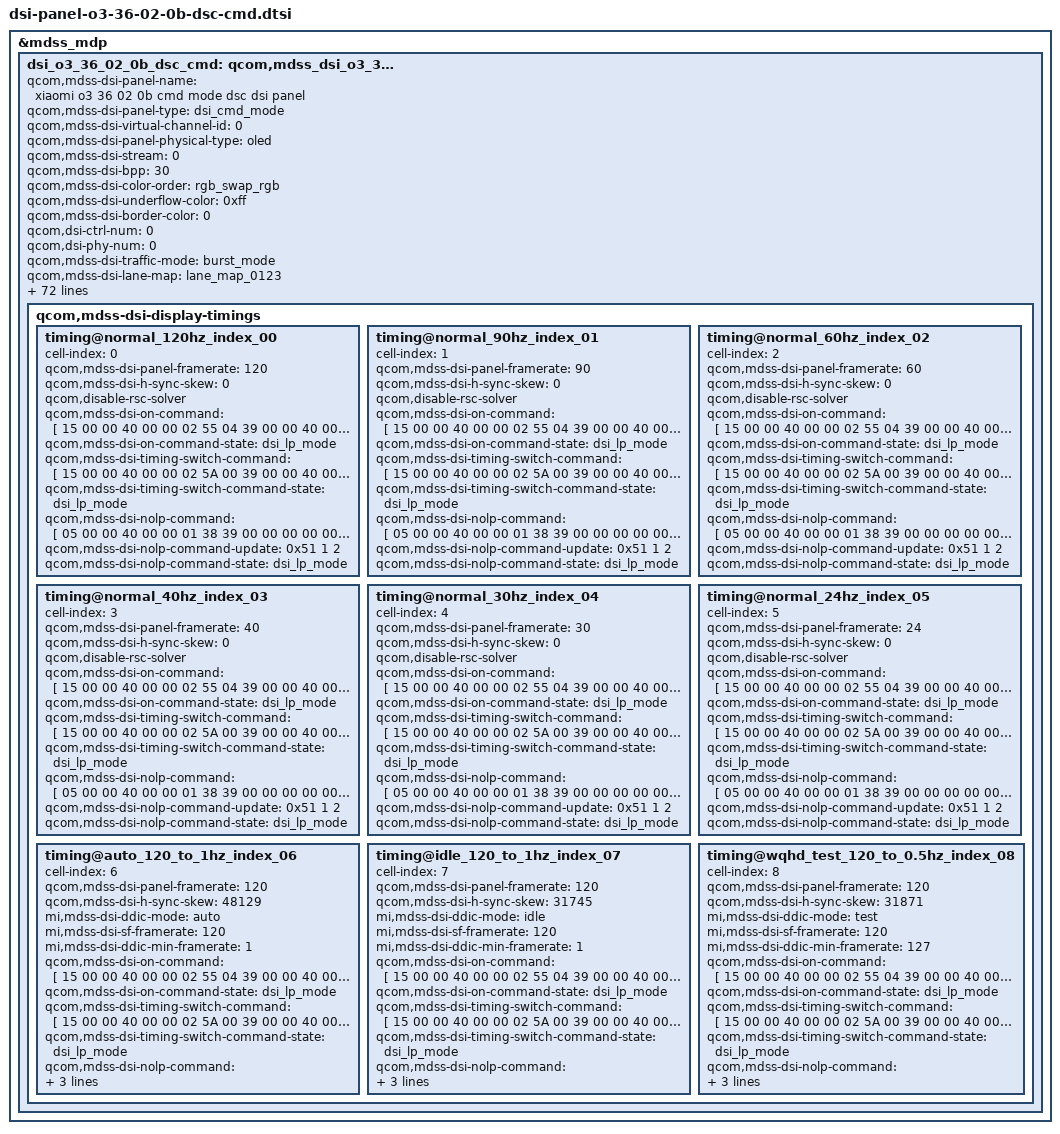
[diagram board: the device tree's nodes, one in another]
&mdss_mdp {
	dsi_o3_36_02_0b_dsc_cmd: qcom,mdss_dsi_o3_36_02_0b_dsc_cmd {
		qcom,mdss-dsi-panel-name = "xiaomi o3 36 02 0b cmd mode dsc dsi panel";
		qcom,mdss-dsi-panel-type = "dsi_cmd_mode";
		qcom,mdss-dsi-virtual-channel-id = <0>;
		qcom,mdss-dsi-panel-physical-type = "oled";
		qcom,mdss-dsi-stream = <0>;
		qcom,mdss-dsi-bpp = <30>;
		qcom,mdss-dsi-color-order = "rgb_swap_rgb";
		qcom,mdss-dsi-underflow-color = <0xff>;
		qcom,mdss-dsi-border-color = <0>;
		qcom,dsi-ctrl-num = <0>;
		qcom,dsi-phy-num = <0>;

		qcom,mdss-dsi-traffic-mode = "burst_mode";
		qcom,mdss-dsi-lane-map = "lane_map_0123";
		qcom,mdss-dsi-bllp-eof-power-mode;
		qcom,mdss-dsi-bllp-power-mode;
		qcom,mdss-dsi-lane-0-state;
		qcom,mdss-dsi-lane-1-state;
		qcom,mdss-dsi-lane-2-state;
		qcom,mdss-dsi-lane-3-state;
		qcom,mdss-dsi-dma-trigger = "trigger_sw";
		qcom,mdss-dsi-mdp-trigger = "none";
		qcom,mdss-dsi-reset-sequence = <1 10>, <0 1>, <1 25>;
		qcom,mdss-pan-physical-width-dimension = <663>;
		qcom,mdss-pan-physical-height-dimension = <1473>;
		qcom,mdss-dsi-te-pin-select = <1>;
		qcom,mdss-dsi-wr-mem-start = <0x2c>;
		qcom,mdss-dsi-wr-mem-continue = <0x3c>;
		qcom,mdss-dsi-te-dcs-command = <1>;
		qcom,mdss-dsi-te-check-enable;
		qcom,mdss-dsi-te-using-te-pin;
		qcom,mdss-dsi-tx-eot-append;
		qcom,mdss-dsi-lp11-init;

		qcom,mdss-dsi-bl-inverted-dbv;
		qcom,bl-update-flag = "delay_until_first_frame";

		qcom,mdss-dsi-dma-schedule-line = <1>;
		qcom,mdss-dsi-dma-schedule-window = <50>;

		mi,panel-id = <0x00004F33 0x0036020B>;

		mi,panel-on-dimming-delay = <120>;
		mi,max-brightness-clone = <16383>;

		mi,need-update-gamma-befor-init;

		qcom,spr-pack-type = "pentile";
		/*
		 * ###############################################################
		 * # Pentile SPR phases for SM8750 and later
		 * ###############################################################
		 * # RG/BG Type A    BG/RG Type A    GR/GB Type A    GB/GR Type A
		 * # R B R B ...     B R B R ...      R B R B ...     B R B R ...
		 * #  G G G G ...     G G G G ...    G G G G ...     G G G G ...
		 * #
		 * # RG/BG Type B    BG/RG Type B    GR/GB Type B    GB/GR Type B
		 * #  G G G G ...     G G G G ...    G G G G ...     G G G G ...
		 * # R B R B ...     B R B R ...      R B R B ...     B R B R ...
		 * ###############################################################
		 */
		qcom,spr-pentile-pack-type = "RG-BG Type A";

		mi,mdss-dsi-panel-wp-read-command = [06 01 00 01 00 00 01 A1];
		mi,mdss-dsi-panel-wp-read-command-state = "dsi_hs_mode";
		mi,mdss-dsi-panel-wp-read-length = <3>;
		mi,mdss-dsi-panel-cell-id-read-command = [06 01 00 01 00 00 01 AC];
		mi,mdss-dsi-panel-cell-id-read-command-state = "dsi_hs_mode";
		mi,mdss-dsi-panel-cell-id-read-length = <16>;

		mi,mdss-dsi-fac-bl-max-level = <2731>;
		mi,mdss-fac-brightness-max-level = <2731>;

		mi,doze-hbm-dbv-level = <207>;
		mi,doze-lbm-dbv-level = <25>;
		/* IRQF_ONESHOT | IRQF_TRIGGER_HEIGH */
		mi,esd-err-irq-gpio = <&tlmm 87 0x2004>;
		mi,esd-err-irq-gpio-flag = <0x2004>;

		mi,dc-feature-enabled;
		mi,ddic-round-corner-enabled;
		qcom,mdss-disable-cesta-hw-sleep;

		qcom,mdss-dsi-display-timings {
			timing@normal_120hz_index_00 {
				#include "dsi-panel-o3-36-02-0b-dsc-cmd-common.dtsi"
				cell-index = <0>;
				qcom,mdss-dsi-panel-framerate = <120>;
				qcom,mdss-dsi-h-sync-skew = <0>;
				qcom,disable-rsc-solver;
				qcom,mdss-dsi-on-command = [
					15 00 00 40 00 00 02 55 04
					39 00 00 40 00 00 03 81 01 19
					15 00 00 40 00 00 02 5A 01
					39 00 00 40 00 00 05 FF AA 55 A5 80
					15 00 00 40 00 00 02 6F 0A
					39 00 00 40 00 00 06 F6 70 70 70 70 70
					39 00 00 40 00 00 05 FF AA 55 A5 81
					15 00 00 40 00 00 02 6F 0D
					15 00 00 40 00 00 02 FB 80
					/*OSC Setting*/
					39 00 00 40 00 00 05 FF AA 55 A5 80
					15 00 00 40 00 00 02 6F 31
					39 00 00 40 00 00 03 F8 01 C4
					39 00 00 40 00 00 05 FF AA 55 A5 80
					15 00 00 40 00 00 02 6F 47
					15 00 00 40 00 00 02 F2 20
					15 00 00 40 00 00 02 6F 05
					15 00 00 40 00 00 02 F8 59
					15 00 00 40 00 00 02 6F 21
					15 00 00 40 00 00 02 F8 59
					39 00 00 40 00 00 05 FF AA 55 A5 81
					15 00 00 40 00 00 02 6F 0C
					15 00 00 40 00 00 02 FD 00
					15 00 00 40 00 00 02 6F 02
					15 00 00 40 00 00 02 F9 84
					15 00 00 40 00 00 02 6F 10
					15 00 00 40 00 00 02 FB 40
					39 00 00 40 00 00 05 FF AA 55 A5 80
					15 00 00 40 00 00 02 6F 48
					15 00 00 40 00 00 02 F2 00
					39 00 00 40 00 00 05 FF AA 55 A5 80
					15 00 00 40 00 00 02 6F 16
					39 00 00 40 00 00 03 F4 02 74
					39 00 00 40 00 00 05 FF AA 55 A5 80
					15 00 00 40 00 00 02 6F 42
					15 00 00 40 00 00 02 F4 00
					39 00 00 40 00 00 05 FF AA 55 A5 80
					15 00 00 40 00 00 02 6F 49
					15 00 00 40 00 00 02 F2 10
					39 00 00 40 00 00 05 FF AA 55 A5 81
					15 00 00 40 00 00 02 6F 05
					39 00 00 40 00 00 03 FE 3C 3C
					39 00 00 40 00 00 05 FF AA 55 A5 82
					15 00 00 40 00 00 02 6F 09
					15 00 00 40 00 00 02 F2 FF
					39 00 00 40 00 00 05 FF AA 55 A5 80
					15 00 00 40 00 00 02 6F 04
					15 00 00 40 00 00 02 F2 3C
					15 00 00 40 00 00 02 17 30
					/*120hz*/
					15 00 00 40 00 00 02 2F 00
					/*TE ON*/
					15 00 00 40 00 00 02 35 00
					/*600nit*/
					39 00 00 40 00 00 03 51 00 00
					15 00 00 40 00 00 02 6F 04
					/*AOD 60nit*/
					39 00 00 40 00 00 03 51 07 FF
					15 00 00 40 00 00 02 53 20
					39 00 00 40 00 00 05 2A 00 00 04 AF
					39 00 00 40 00 00 05 2B 00 00 0A 6D
					39 00 00 40 00 00 06 F0 55 AA 52 08 03
					15 00 00 00 00 00 02 6F 09
					39 00 00 40 00 00 07 DE 30 14 25 10 34 25
					39 00 00 40 00 00 06 F0 55 AA 52 08 07
					15 00 00 40 00 00 02 B0 04
					//Vesa YUV 1.2 8_16 VESASPEC_1200x2670, slice 30
					15 00 00 40 00 00 02 90 03
					15 00 00 40 00 00 02 6F 01
					15 00 00 40 00 00 02 90 43
					39 00 00 40 00 00 13 91 AB F0 00 1E D1 00 01 D2 00 D4 00 32 03 97 11 48 11 50
					39 00 00 40 00 00 06 F0 55 AA 52 08 01
					15 00 00 40 00 00 02 6F 02
					/*lvd off*/
					39 00 00 40 00 00 03 C7 00 00
					/*GIR ON*/
					39 00 00 40 00 00 03 5F 00 00
					/*normal Gramma*/
					15 00 00 40 00 00 02 26 00
					/*Skip mode setting*/
					39 00 00 00 00 00 06 F0 55 AA 52 08 00
					15 00 00 40 00 00 02 6F 1C
					39 00 00 40 00 00 11 BA 01 01 01 01 01 01 01 03 01 01 01 03 00 00 00 00
					15 00 00 40 00 00 02 6F 2C
					39 00 00 40 00 00 11 BA 01 01 01 01 01 03 03 01 01 03 03 01 00 00 00 00
					15 00 00 40 00 00 02 6F 3C
					39 00 00 40 00 00 11 BA 01 01 01 01 01 04 04 03 01 04 04 03 00 00 00 00
					15 00 00 40 00 00 02 6F 4C
					39 00 00 40 00 00 11 BA 01 01 01 01 0B 0B 0B 0B 0B 0B 0B 0B 00 00 00 00
					15 00 00 40 00 00 02 6F 5C
					39 00 00 40 00 00 11 BA 01 01 01 01 01 01 01 01 01 01 01 01 01 01 01 01
					15 00 00 40 00 00 02 6F 6C
					39 00 00 40 00 00 09 BA 00 00 00 00 00 00 00 00
					15 00 00 40 00 00 02 6F 74
					39 00 00 40 00 00 11 BA 00 01 02 03 04 05 07 09 0B 77 EF 00 03 0B 0B 03
					15 00 00 40 00 00 02 6F 84
					39 00 00 40 00 00 11 BA 00 01 02 03 04 05 07 09 0B 77 EF 00 03 0B 0B 03
					15 00 00 40 00 00 02 6F 94
					39 00 00 40 00 00 11 BA 00 00 00 00 00 00 00 00 00 00 00 00 00 00 00 00
					15 00 00 40 00 00 02 6F A4
					39 00 00 40 00 00 11 BA 01 01 01 01 00 01 01 00 00 01 01 00 00 00 1E 00
					15 00 00 40 00 00 02 6F B4
					39 00 00 40 00 00 05 BA 00 55 19 0C
					15 00 00 40 00 00 02 6F B8
					39 00 00 40 00 00 09 BA 00 00 00 00 00 10 00 00
					15 00 00 40 00 00 02 6F C0
					39 00 00 40 00 00 09 BA 00 00 00 00 00 10 00 00
					15 00 00 40 00 00 02 6F 6E
					39 00 00 40 00 00 03 D1 03 C8
					15 00 00 40 00 00 02 2F 30
					/*120hz*/
					15 00 00 40 00 00 02 5A 00
					39 00 00 40 00 00 06 F0 55 AA 52 08 00
					15 00 00 40 00 00 02 6F DE
					15 00 00 40 00 00 02 BA 00
					15 00 00 40 00 00 02 6F 04
					15 00 00 40 00 00 02 35 00
					15 00 00 40 00 00 02 6F 14
					15 00 00 40 00 00 02 35 00
					15 00 00 40 00 00 02 8C 00
					15 00 00 00 00 00 02 6D 00
					/* ACL On */
					39 00 00 40 00 00 06 F0 55 AA 52 08 00
					15 00 00 40 00 00 02 6F 17
					39 00 00 40 00 00 0B B0 1A AF 1C 03 1D 57 1E AB 1F FF
					15 00 00 40 00 00 02 6F 25
					39 00 00 00 00 00 0D B0 01 FF 01 65 01 65 01 65 01 65 01 65
					15 00 00 40 00 00 02 6F 55
					39 00 00 00 00 00 07 B0 00 00 0D 18 23 2C
					/* Display On */
					05 00 00 00 78 00 01 11
					05 00 00 00 00 00 01 29
				];
				qcom,mdss-dsi-on-command-state = "dsi_lp_mode";

				qcom,mdss-dsi-timing-switch-command = [
					15 00 00 40 00 00 02 5A 00
					39 00 00 40 00 00 06 F0 55 AA 52 08 00
					15 00 00 40 00 00 02 6F DE
					15 00 00 40 00 00 02 BA 00
					15 00 00 40 00 00 02 6F 04
					15 00 00 40 00 00 02 35 00
					15 00 00 40 00 00 02 6F 14
					15 00 00 40 00 00 02 35 00
					15 00 00 40 00 00 02 8C 00
					15 00 00 00 00 00 02 6D 00
				];
				qcom,mdss-dsi-timing-switch-command-state = "dsi_lp_mode";

				qcom,mdss-dsi-nolp-command = [
					05 00 00 40 00 00 01 38
					39 00 00 00 00 00 03 51 00 00
				];
				qcom,mdss-dsi-nolp-command-update = <0x51 1 2>;
				qcom,mdss-dsi-nolp-command-state = "dsi_lp_mode";
			};

			timing@normal_90hz_index_01 {
				#include "dsi-panel-o3-36-02-0b-dsc-cmd-common.dtsi"
				cell-index = <1>;
				qcom,mdss-dsi-panel-framerate = <90>;
				qcom,mdss-dsi-h-sync-skew = <0>;
				qcom,disable-rsc-solver;
				qcom,mdss-dsi-on-command = [
					15 00 00 40 00 00 02 55 04
					39 00 00 40 00 00 03 81 01 19
					15 00 00 40 00 00 02 5A 01
					39 00 00 40 00 00 05 FF AA 55 A5 80
					15 00 00 40 00 00 02 6F 0A
					39 00 00 40 00 00 06 F6 70 70 70 70 70
					39 00 00 40 00 00 05 FF AA 55 A5 81
					15 00 00 40 00 00 02 6F 0D
					15 00 00 40 00 00 02 FB 80
					/*OSC Setting*/
					39 00 00 40 00 00 05 FF AA 55 A5 80
					15 00 00 40 00 00 02 6F 31
					39 00 00 40 00 00 03 F8 01 C4
					39 00 00 40 00 00 05 FF AA 55 A5 80
					15 00 00 40 00 00 02 6F 47
					15 00 00 40 00 00 02 F2 20
					15 00 00 40 00 00 02 6F 05
					15 00 00 40 00 00 02 F8 59
					15 00 00 40 00 00 02 6F 21
					15 00 00 40 00 00 02 F8 59
					39 00 00 40 00 00 05 FF AA 55 A5 81
					15 00 00 40 00 00 02 6F 0C
					15 00 00 40 00 00 02 FD 00
					15 00 00 40 00 00 02 6F 02
					15 00 00 40 00 00 02 F9 84
					15 00 00 40 00 00 02 6F 10
					15 00 00 40 00 00 02 FB 40
					39 00 00 40 00 00 05 FF AA 55 A5 80
					15 00 00 40 00 00 02 6F 48
					15 00 00 40 00 00 02 F2 00
					39 00 00 40 00 00 05 FF AA 55 A5 80
					15 00 00 40 00 00 02 6F 16
					39 00 00 40 00 00 03 F4 02 74
					39 00 00 40 00 00 05 FF AA 55 A5 80
					15 00 00 40 00 00 02 6F 42
					15 00 00 40 00 00 02 F4 00
					39 00 00 40 00 00 05 FF AA 55 A5 80
					15 00 00 40 00 00 02 6F 49
					15 00 00 40 00 00 02 F2 10
					39 00 00 40 00 00 05 FF AA 55 A5 81
					15 00 00 40 00 00 02 6F 05
					39 00 00 40 00 00 03 FE 3C 3C
					39 00 00 40 00 00 05 FF AA 55 A5 82
					15 00 00 40 00 00 02 6F 09
					15 00 00 40 00 00 02 F2 FF
					39 00 00 40 00 00 05 FF AA 55 A5 80
					15 00 00 40 00 00 02 6F 04
					15 00 00 40 00 00 02 F2 3C
					15 00 00 40 00 00 02 17 30
					/*120hz*/
					15 00 00 40 00 00 02 2F 00
					/*TE ON*/
					15 00 00 40 00 00 02 35 00
					/*600nit*/
					39 00 00 40 00 00 03 51 00 00
					15 00 00 40 00 00 02 6F 04
					/*AOD 60nit*/
					39 00 00 40 00 00 03 51 07 FF
					15 00 00 40 00 00 02 53 20
					39 00 00 40 00 00 05 2A 00 00 04 AF
					39 00 00 40 00 00 05 2B 00 00 0A 6D
					39 00 00 40 00 00 06 F0 55 AA 52 08 03
					15 00 00 00 00 00 02 6F 09
					39 00 00 40 00 00 07 DE 30 14 25 10 34 25
					39 00 00 40 00 00 06 F0 55 AA 52 08 07
					15 00 00 40 00 00 02 B0 04
					//Vesa YUV 1.2 8_16 VESASPEC_1200x2670, slice 30
					15 00 00 40 00 00 02 90 03
					15 00 00 40 00 00 02 6F 01
					15 00 00 40 00 00 02 90 43
					39 00 00 40 00 00 13 91 AB F0 00 1E D1 00 01 D2 00 D4 00 32 03 97 11 48 11 50
					39 00 00 40 00 00 06 F0 55 AA 52 08 01
					15 00 00 40 00 00 02 6F 02
					/*lvd off*/
					39 00 00 40 00 00 03 C7 00 00
					/*GIR ON*/
					39 00 00 40 00 00 03 5F 00 00
					/*normal Gramma*/
					15 00 00 40 00 00 02 26 00
					/*Skip mode setting*/
					39 00 00 00 00 00 06 F0 55 AA 52 08 00
					15 00 00 40 00 00 02 6F 1C
					39 00 00 40 00 00 11 BA 01 01 01 01 01 01 01 03 01 01 01 03 00 00 00 00
					15 00 00 40 00 00 02 6F 2C
					39 00 00 40 00 00 11 BA 01 01 01 01 01 03 03 01 01 03 03 01 00 00 00 00
					15 00 00 40 00 00 02 6F 3C
					39 00 00 40 00 00 11 BA 01 01 01 01 01 04 04 03 01 04 04 03 00 00 00 00
					15 00 00 40 00 00 02 6F 4C
					39 00 00 40 00 00 11 BA 01 01 01 01 0B 0B 0B 0B 0B 0B 0B 0B 00 00 00 00
					15 00 00 40 00 00 02 6F 5C
					39 00 00 40 00 00 11 BA 01 01 01 01 01 01 01 01 01 01 01 01 01 01 01 01
					15 00 00 40 00 00 02 6F 6C
					39 00 00 40 00 00 09 BA 00 00 00 00 00 00 00 00
					15 00 00 40 00 00 02 6F 74
					39 00 00 40 00 00 11 BA 00 01 02 03 04 05 07 09 0B 77 EF 00 03 0B 0B 03
					15 00 00 40 00 00 02 6F 84
					39 00 00 40 00 00 11 BA 00 01 02 03 04 05 07 09 0B 77 EF 00 03 0B 0B 03
					15 00 00 40 00 00 02 6F 94
					39 00 00 40 00 00 11 BA 00 00 00 00 00 00 00 00 00 00 00 00 00 00 00 00
					15 00 00 40 00 00 02 6F A4
					39 00 00 40 00 00 11 BA 01 01 01 01 00 01 01 00 00 01 01 00 00 00 1E 00
					15 00 00 40 00 00 02 6F B4
					39 00 00 40 00 00 05 BA 00 55 19 0C
					15 00 00 40 00 00 02 6F B8
					39 00 00 40 00 00 09 BA 00 00 00 00 00 10 00 00
					15 00 00 40 00 00 02 6F C0
					39 00 00 40 00 00 09 BA 00 00 00 00 00 10 00 00
					15 00 00 40 00 00 02 6F 6E
					39 00 00 40 00 00 03 D1 03 C8
					15 00 00 40 00 00 02 2F 30
					/*90hz*/
					15 00 00 40 00 00 02 5A 00
					39 00 00 40 00 00 06 F0 55 AA 52 08 00
					15 00 00 40 00 00 02 6F DE
					15 00 00 40 00 00 02 BA 04
					15 00 00 40 00 00 02 6F 04
					15 00 00 40 00 00 02 35 00
					15 00 00 40 00 00 02 6F 14
					15 00 00 40 00 00 02 35 00
					15 00 00 40 00 00 02 8C 00
					15 00 00 00 00 00 02 6D 0B
					/* ACL On */
					39 00 00 40 00 00 06 F0 55 AA 52 08 00
					15 00 00 40 00 00 02 6F 17
					39 00 00 40 00 00 0B B0 1A AF 1C 03 1D 57 1E AB 1F FF
					15 00 00 40 00 00 02 6F 25
					39 00 00 00 00 00 0D B0 01 FF 01 65 01 65 01 65 01 65 01 65
					15 00 00 40 00 00 02 6F 55
					39 00 00 00 00 00 07 B0 00 00 0D 18 23 2C
					/* Display On */
					05 00 00 00 78 00 01 11
					05 00 00 00 00 00 01 29
				];
				qcom,mdss-dsi-on-command-state = "dsi_lp_mode";

				qcom,mdss-dsi-timing-switch-command = [
					15 00 00 40 00 00 02 5A 00
					39 00 00 40 00 00 06 F0 55 AA 52 08 00
					15 00 00 40 00 00 02 6F DE
					15 00 00 40 00 00 02 BA 04
					15 00 00 40 00 00 02 6F 04
					15 00 00 40 00 00 02 35 00
					15 00 00 40 00 00 02 6F 14
					15 00 00 40 00 00 02 35 00
					15 00 00 40 00 00 02 8C 00
					15 00 00 00 00 00 02 6D 0B
				];
				qcom,mdss-dsi-timing-switch-command-state = "dsi_lp_mode";

				qcom,mdss-dsi-nolp-command = [
					05 00 00 40 00 00 01 38
					39 00 00 00 00 00 03 51 00 00
				];
				qcom,mdss-dsi-nolp-command-update = <0x51 1 2>;
				qcom,mdss-dsi-nolp-command-state = "dsi_lp_mode";
			};

			timing@normal_60hz_index_02 {
				#include "dsi-panel-o3-36-02-0b-dsc-cmd-common.dtsi"
				cell-index = <2>;
				qcom,mdss-dsi-panel-framerate = <60>;
				qcom,mdss-dsi-h-sync-skew = <0>;
				qcom,disable-rsc-solver;
				qcom,mdss-dsi-on-command = [
					15 00 00 40 00 00 02 55 04
					39 00 00 40 00 00 03 81 01 19
					15 00 00 40 00 00 02 5A 01
					39 00 00 40 00 00 05 FF AA 55 A5 80
					15 00 00 40 00 00 02 6F 0A
					39 00 00 40 00 00 06 F6 70 70 70 70 70
					39 00 00 40 00 00 05 FF AA 55 A5 81
					15 00 00 40 00 00 02 6F 0D
					15 00 00 40 00 00 02 FB 80
					/*OSC Setting*/
					39 00 00 40 00 00 05 FF AA 55 A5 80
					15 00 00 40 00 00 02 6F 31
					39 00 00 40 00 00 03 F8 01 C4
					39 00 00 40 00 00 05 FF AA 55 A5 80
					15 00 00 40 00 00 02 6F 47
					15 00 00 40 00 00 02 F2 20
					15 00 00 40 00 00 02 6F 05
					15 00 00 40 00 00 02 F8 59
					15 00 00 40 00 00 02 6F 21
					15 00 00 40 00 00 02 F8 59
					39 00 00 40 00 00 05 FF AA 55 A5 81
					15 00 00 40 00 00 02 6F 0C
					15 00 00 40 00 00 02 FD 00
					15 00 00 40 00 00 02 6F 02
					15 00 00 40 00 00 02 F9 84
					15 00 00 40 00 00 02 6F 10
					15 00 00 40 00 00 02 FB 40
					39 00 00 40 00 00 05 FF AA 55 A5 80
					15 00 00 40 00 00 02 6F 48
					15 00 00 40 00 00 02 F2 00
					39 00 00 40 00 00 05 FF AA 55 A5 80
					15 00 00 40 00 00 02 6F 16
					39 00 00 40 00 00 03 F4 02 74
					39 00 00 40 00 00 05 FF AA 55 A5 80
					15 00 00 40 00 00 02 6F 42
					15 00 00 40 00 00 02 F4 00
					39 00 00 40 00 00 05 FF AA 55 A5 80
					15 00 00 40 00 00 02 6F 49
					15 00 00 40 00 00 02 F2 10
					39 00 00 40 00 00 05 FF AA 55 A5 81
					15 00 00 40 00 00 02 6F 05
					39 00 00 40 00 00 03 FE 3C 3C
					39 00 00 40 00 00 05 FF AA 55 A5 82
					15 00 00 40 00 00 02 6F 09
					15 00 00 40 00 00 02 F2 FF
					39 00 00 40 00 00 05 FF AA 55 A5 80
					15 00 00 40 00 00 02 6F 04
					15 00 00 40 00 00 02 F2 3C
					15 00 00 40 00 00 02 17 30
					/*120hz*/
					15 00 00 40 00 00 02 2F 00
					/*TE ON*/
					15 00 00 40 00 00 02 35 00
					/*600nit*/
					39 00 00 40 00 00 03 51 00 00
					15 00 00 40 00 00 02 6F 04
					/*AOD 60nit*/
					39 00 00 40 00 00 03 51 07 FF
					15 00 00 40 00 00 02 53 20
					39 00 00 40 00 00 05 2A 00 00 04 AF
					39 00 00 40 00 00 05 2B 00 00 0A 6D
					39 00 00 40 00 00 06 F0 55 AA 52 08 03
					15 00 00 00 00 00 02 6F 09
					39 00 00 40 00 00 07 DE 30 14 25 10 34 25
					39 00 00 40 00 00 06 F0 55 AA 52 08 07
					15 00 00 40 00 00 02 B0 04
					//Vesa YUV 1.2 8_16 VESASPEC_1200x2670, slice 30
					15 00 00 40 00 00 02 90 03
					15 00 00 40 00 00 02 6F 01
					15 00 00 40 00 00 02 90 43
					39 00 00 40 00 00 13 91 AB F0 00 1E D1 00 01 D2 00 D4 00 32 03 97 11 48 11 50
					39 00 00 40 00 00 06 F0 55 AA 52 08 01
					15 00 00 40 00 00 02 6F 02
					/*lvd off*/
					39 00 00 40 00 00 03 C7 00 00
					/*GIR ON*/
					39 00 00 40 00 00 03 5F 00 00
					/*normal Gramma*/
					15 00 00 40 00 00 02 26 00
					/*Skip mode setting*/
					39 00 00 00 00 00 06 F0 55 AA 52 08 00
					15 00 00 40 00 00 02 6F 1C
					39 00 00 40 00 00 11 BA 01 01 01 01 01 01 01 03 01 01 01 03 00 00 00 00
					15 00 00 40 00 00 02 6F 2C
					39 00 00 40 00 00 11 BA 01 01 01 01 01 03 03 01 01 03 03 01 00 00 00 00
					15 00 00 40 00 00 02 6F 3C
					39 00 00 40 00 00 11 BA 01 01 01 01 01 04 04 03 01 04 04 03 00 00 00 00
					15 00 00 40 00 00 02 6F 4C
					39 00 00 40 00 00 11 BA 01 01 01 01 0B 0B 0B 0B 0B 0B 0B 0B 00 00 00 00
					15 00 00 40 00 00 02 6F 5C
					39 00 00 40 00 00 11 BA 01 01 01 01 01 01 01 01 01 01 01 01 01 01 01 01
					15 00 00 40 00 00 02 6F 6C
					39 00 00 40 00 00 09 BA 00 00 00 00 00 00 00 00
					15 00 00 40 00 00 02 6F 74
					39 00 00 40 00 00 11 BA 00 01 02 03 04 05 07 09 0B 77 EF 00 03 0B 0B 03
					15 00 00 40 00 00 02 6F 84
					39 00 00 40 00 00 11 BA 00 01 02 03 04 05 07 09 0B 77 EF 00 03 0B 0B 03
					15 00 00 40 00 00 02 6F 94
					39 00 00 40 00 00 11 BA 00 00 00 00 00 00 00 00 00 00 00 00 00 00 00 00
					15 00 00 40 00 00 02 6F A4
					39 00 00 40 00 00 11 BA 01 01 01 01 00 01 01 00 00 01 01 00 00 00 1E 00
					15 00 00 40 00 00 02 6F B4
					39 00 00 40 00 00 05 BA 00 55 19 0C
					15 00 00 40 00 00 02 6F B8
					39 00 00 40 00 00 09 BA 00 00 00 00 00 10 00 00
					15 00 00 40 00 00 02 6F C0
					39 00 00 40 00 00 09 BA 00 00 00 00 00 10 00 00
					15 00 00 40 00 00 02 6F 6E
					39 00 00 40 00 00 03 D1 03 C8
					15 00 00 40 00 00 02 2F 30
					/*60hz*/
					15 00 00 40 00 00 02 5A 00
					39 00 00 40 00 00 06 F0 55 AA 52 08 00
					15 00 00 40 00 00 02 6F DE
					15 00 00 40 00 00 02 BA 04
					15 00 00 40 00 00 02 6F 04
					15 00 00 40 00 00 02 35 01
					15 00 00 40 00 00 02 6F 14
					15 00 00 40 00 00 02 35 00
					15 00 00 40 00 00 02 8C 02
					15 00 00 00 00 00 02 6D 01
					/* ACL On */
					39 00 00 40 00 00 06 F0 55 AA 52 08 00
					15 00 00 40 00 00 02 6F 17
					39 00 00 40 00 00 0B B0 1A AF 1C 03 1D 57 1E AB 1F FF
					15 00 00 40 00 00 02 6F 25
					39 00 00 00 00 00 0D B0 01 FF 01 65 01 65 01 65 01 65 01 65
					15 00 00 40 00 00 02 6F 55
					39 00 00 00 00 00 07 B0 00 00 0D 18 23 2C
					/* Display On */
					05 00 00 00 78 00 01 11
					05 00 00 00 00 00 01 29
				];
				qcom,mdss-dsi-on-command-state = "dsi_lp_mode";

				qcom,mdss-dsi-timing-switch-command = [
					15 00 00 40 00 00 02 5A 00
					39 00 00 40 00 00 06 F0 55 AA 52 08 00
					15 00 00 40 00 00 02 6F DE
					15 00 00 40 00 00 02 BA 04
					15 00 00 40 00 00 02 6F 04
					15 00 00 40 00 00 02 35 01
					15 00 00 40 00 00 02 6F 14
					15 00 00 40 00 00 02 35 00
					15 00 00 40 00 00 02 8C 02
					15 00 00 00 00 00 02 6D 01
				];
				qcom,mdss-dsi-timing-switch-command-state = "dsi_lp_mode";

				qcom,mdss-dsi-nolp-command = [
					05 00 00 40 00 00 01 38
					39 00 00 00 00 00 03 51 00 00
				];
				qcom,mdss-dsi-nolp-command-update = <0x51 1 2>;
				qcom,mdss-dsi-nolp-command-state = "dsi_lp_mode";
			};

			timing@normal_40hz_index_03 {
				#include "dsi-panel-o3-36-02-0b-dsc-cmd-common.dtsi"
				cell-index = <3>;
				qcom,mdss-dsi-panel-framerate = <40>;
				qcom,mdss-dsi-h-sync-skew = <0>;
				qcom,disable-rsc-solver;
				qcom,mdss-dsi-on-command = [
					15 00 00 40 00 00 02 55 04
					39 00 00 40 00 00 03 81 01 19
					15 00 00 40 00 00 02 5A 01
					39 00 00 40 00 00 05 FF AA 55 A5 80
					15 00 00 40 00 00 02 6F 0A
					39 00 00 40 00 00 06 F6 70 70 70 70 70
					39 00 00 40 00 00 05 FF AA 55 A5 81
					15 00 00 40 00 00 02 6F 0D
					15 00 00 40 00 00 02 FB 80
					/*OSC Setting*/
					39 00 00 40 00 00 05 FF AA 55 A5 80
					15 00 00 40 00 00 02 6F 31
					39 00 00 40 00 00 03 F8 01 C4
					39 00 00 40 00 00 05 FF AA 55 A5 80
					15 00 00 40 00 00 02 6F 47
					15 00 00 40 00 00 02 F2 20
					15 00 00 40 00 00 02 6F 05
					15 00 00 40 00 00 02 F8 59
					15 00 00 40 00 00 02 6F 21
					15 00 00 40 00 00 02 F8 59
					39 00 00 40 00 00 05 FF AA 55 A5 81
					15 00 00 40 00 00 02 6F 0C
					15 00 00 40 00 00 02 FD 00
					15 00 00 40 00 00 02 6F 02
					15 00 00 40 00 00 02 F9 84
					15 00 00 40 00 00 02 6F 10
					15 00 00 40 00 00 02 FB 40
					39 00 00 40 00 00 05 FF AA 55 A5 80
					15 00 00 40 00 00 02 6F 48
					15 00 00 40 00 00 02 F2 00
					39 00 00 40 00 00 05 FF AA 55 A5 80
					15 00 00 40 00 00 02 6F 16
					39 00 00 40 00 00 03 F4 02 74
					39 00 00 40 00 00 05 FF AA 55 A5 80
					15 00 00 40 00 00 02 6F 42
					15 00 00 40 00 00 02 F4 00
					39 00 00 40 00 00 05 FF AA 55 A5 80
					15 00 00 40 00 00 02 6F 49
					15 00 00 40 00 00 02 F2 10
					39 00 00 40 00 00 05 FF AA 55 A5 81
					15 00 00 40 00 00 02 6F 05
					39 00 00 40 00 00 03 FE 3C 3C
					39 00 00 40 00 00 05 FF AA 55 A5 82
					15 00 00 40 00 00 02 6F 09
					15 00 00 40 00 00 02 F2 FF
					39 00 00 40 00 00 05 FF AA 55 A5 80
					15 00 00 40 00 00 02 6F 04
					15 00 00 40 00 00 02 F2 3C
					15 00 00 40 00 00 02 17 30
					/*120hz*/
					15 00 00 40 00 00 02 2F 00
					/*TE ON*/
					15 00 00 40 00 00 02 35 00
					/*600nit*/
					39 00 00 40 00 00 03 51 00 00
					15 00 00 40 00 00 02 6F 04
					/*AOD 60nit*/
					39 00 00 40 00 00 03 51 07 FF
					15 00 00 40 00 00 02 53 20
					39 00 00 40 00 00 05 2A 00 00 04 AF
					39 00 00 40 00 00 05 2B 00 00 0A 6D
					39 00 00 40 00 00 06 F0 55 AA 52 08 03
					15 00 00 00 00 00 02 6F 09
					39 00 00 40 00 00 07 DE 30 14 25 10 34 25
					39 00 00 40 00 00 06 F0 55 AA 52 08 07
					15 00 00 40 00 00 02 B0 04
					//Vesa YUV 1.2 8_16 VESASPEC_1200x2670, slice 30
					15 00 00 40 00 00 02 90 03
					15 00 00 40 00 00 02 6F 01
					15 00 00 40 00 00 02 90 43
					39 00 00 40 00 00 13 91 AB F0 00 1E D1 00 01 D2 00 D4 00 32 03 97 11 48 11 50
					39 00 00 40 00 00 06 F0 55 AA 52 08 01
					15 00 00 40 00 00 02 6F 02
					/*lvd off*/
					39 00 00 40 00 00 03 C7 00 00
					/*GIR ON*/
					39 00 00 40 00 00 03 5F 00 00
					/*normal Gramma*/
					15 00 00 40 00 00 02 26 00
					/*Skip mode setting*/
					39 00 00 00 00 00 06 F0 55 AA 52 08 00
					15 00 00 40 00 00 02 6F 1C
					39 00 00 40 00 00 11 BA 01 01 01 01 01 01 01 03 01 01 01 03 00 00 00 00
					15 00 00 40 00 00 02 6F 2C
					39 00 00 40 00 00 11 BA 01 01 01 01 01 03 03 01 01 03 03 01 00 00 00 00
					15 00 00 40 00 00 02 6F 3C
					39 00 00 40 00 00 11 BA 01 01 01 01 01 04 04 03 01 04 04 03 00 00 00 00
					15 00 00 40 00 00 02 6F 4C
					39 00 00 40 00 00 11 BA 01 01 01 01 0B 0B 0B 0B 0B 0B 0B 0B 00 00 00 00
					15 00 00 40 00 00 02 6F 5C
					39 00 00 40 00 00 11 BA 01 01 01 01 01 01 01 01 01 01 01 01 01 01 01 01
					15 00 00 40 00 00 02 6F 6C
					39 00 00 40 00 00 09 BA 00 00 00 00 00 00 00 00
					15 00 00 40 00 00 02 6F 74
					39 00 00 40 00 00 11 BA 00 01 02 03 04 05 07 09 0B 77 EF 00 03 0B 0B 03
					15 00 00 40 00 00 02 6F 84
					39 00 00 40 00 00 11 BA 00 01 02 03 04 05 07 09 0B 77 EF 00 03 0B 0B 03
					15 00 00 40 00 00 02 6F 94
					39 00 00 40 00 00 11 BA 00 00 00 00 00 00 00 00 00 00 00 00 00 00 00 00
					15 00 00 40 00 00 02 6F A4
					39 00 00 40 00 00 11 BA 01 01 01 01 00 01 01 00 00 01 01 00 00 00 1E 00
					15 00 00 40 00 00 02 6F B4
					39 00 00 40 00 00 05 BA 00 55 19 0C
					15 00 00 40 00 00 02 6F B8
					39 00 00 40 00 00 09 BA 00 00 00 00 00 10 00 00
					15 00 00 40 00 00 02 6F C0
					39 00 00 40 00 00 09 BA 00 00 00 00 00 10 00 00
					15 00 00 40 00 00 02 6F 6E
					39 00 00 40 00 00 03 D1 03 C8
					15 00 00 40 00 00 02 2F 30
					/*40hz*/
					15 00 00 40 00 00 02 5A 00
					39 00 00 40 00 00 06 F0 55 AA 52 08 00
					15 00 00 40 00 00 02 6F DE
					15 00 00 40 00 00 02 BA 04
					15 00 00 40 00 00 02 6F 04
					15 00 00 40 00 00 02 35 02
					15 00 00 40 00 00 02 6F 14
					15 00 00 40 00 00 02 35 00
					15 00 00 40 00 00 02 8C 02
					15 00 00 00 00 00 02 6D 02
					/* ACL On */
					39 00 00 40 00 00 06 F0 55 AA 52 08 00
					15 00 00 40 00 00 02 6F 17
					39 00 00 40 00 00 0B B0 1A AF 1C 03 1D 57 1E AB 1F FF
					15 00 00 40 00 00 02 6F 25
					39 00 00 00 00 00 0D B0 01 FF 01 65 01 65 01 65 01 65 01 65
					15 00 00 40 00 00 02 6F 55
					39 00 00 00 00 00 07 B0 00 00 0D 18 23 2C
					/* Display On */
					05 00 00 00 78 00 01 11
					05 00 00 00 00 00 01 29
				];
				qcom,mdss-dsi-on-command-state = "dsi_lp_mode";

				qcom,mdss-dsi-timing-switch-command = [
					15 00 00 40 00 00 02 5A 00
					39 00 00 40 00 00 06 F0 55 AA 52 08 00
					15 00 00 40 00 00 02 6F DE
					15 00 00 40 00 00 02 BA 04
					15 00 00 40 00 00 02 6F 04
					15 00 00 40 00 00 02 35 02
					15 00 00 40 00 00 02 6F 14
					15 00 00 40 00 00 02 35 00
					15 00 00 40 00 00 02 8C 02
					15 00 00 00 00 00 02 6D 02
				];
				qcom,mdss-dsi-timing-switch-command-state = "dsi_lp_mode";

				qcom,mdss-dsi-nolp-command = [
					05 00 00 40 00 00 01 38
					39 00 00 00 00 00 03 51 00 00
				];
				qcom,mdss-dsi-nolp-command-update = <0x51 1 2>;
				qcom,mdss-dsi-nolp-command-state = "dsi_lp_mode";
			};

			timing@normal_30hz_index_04 {
				#include "dsi-panel-o3-36-02-0b-dsc-cmd-common.dtsi"
				cell-index = <4>;
				qcom,mdss-dsi-panel-framerate = <30>;
				qcom,mdss-dsi-h-sync-skew = <0>;
				qcom,disable-rsc-solver;
				qcom,mdss-dsi-on-command = [
					15 00 00 40 00 00 02 55 04
					39 00 00 40 00 00 03 81 01 19
					15 00 00 40 00 00 02 5A 01
					39 00 00 40 00 00 05 FF AA 55 A5 80
					15 00 00 40 00 00 02 6F 0A
					39 00 00 40 00 00 06 F6 70 70 70 70 70
					39 00 00 40 00 00 05 FF AA 55 A5 81
					15 00 00 40 00 00 02 6F 0D
					15 00 00 40 00 00 02 FB 80
					/*OSC Setting*/
					39 00 00 40 00 00 05 FF AA 55 A5 80
					15 00 00 40 00 00 02 6F 31
					39 00 00 40 00 00 03 F8 01 C4
					39 00 00 40 00 00 05 FF AA 55 A5 80
					15 00 00 40 00 00 02 6F 47
					15 00 00 40 00 00 02 F2 20
					15 00 00 40 00 00 02 6F 05
					15 00 00 40 00 00 02 F8 59
					15 00 00 40 00 00 02 6F 21
					15 00 00 40 00 00 02 F8 59
					39 00 00 40 00 00 05 FF AA 55 A5 81
					15 00 00 40 00 00 02 6F 0C
					15 00 00 40 00 00 02 FD 00
					15 00 00 40 00 00 02 6F 02
					15 00 00 40 00 00 02 F9 84
					15 00 00 40 00 00 02 6F 10
					15 00 00 40 00 00 02 FB 40
					39 00 00 40 00 00 05 FF AA 55 A5 80
					15 00 00 40 00 00 02 6F 48
					15 00 00 40 00 00 02 F2 00
					39 00 00 40 00 00 05 FF AA 55 A5 80
					15 00 00 40 00 00 02 6F 16
					39 00 00 40 00 00 03 F4 02 74
					39 00 00 40 00 00 05 FF AA 55 A5 80
					15 00 00 40 00 00 02 6F 42
					15 00 00 40 00 00 02 F4 00
					39 00 00 40 00 00 05 FF AA 55 A5 80
					15 00 00 40 00 00 02 6F 49
					15 00 00 40 00 00 02 F2 10
					39 00 00 40 00 00 05 FF AA 55 A5 81
					15 00 00 40 00 00 02 6F 05
					39 00 00 40 00 00 03 FE 3C 3C
					39 00 00 40 00 00 05 FF AA 55 A5 82
					15 00 00 40 00 00 02 6F 09
					15 00 00 40 00 00 02 F2 FF
					39 00 00 40 00 00 05 FF AA 55 A5 80
					15 00 00 40 00 00 02 6F 04
					15 00 00 40 00 00 02 F2 3C
					15 00 00 40 00 00 02 17 30
					/*120hz*/
					15 00 00 40 00 00 02 2F 00
					/*TE ON*/
					15 00 00 40 00 00 02 35 00
					/*600nit*/
					39 00 00 40 00 00 03 51 00 00
					15 00 00 40 00 00 02 6F 04
					/*AOD 60nit*/
					39 00 00 40 00 00 03 51 07 FF
					15 00 00 40 00 00 02 53 20
					39 00 00 40 00 00 05 2A 00 00 04 AF
					39 00 00 40 00 00 05 2B 00 00 0A 6D
					39 00 00 40 00 00 06 F0 55 AA 52 08 03
					15 00 00 00 00 00 02 6F 09
					39 00 00 40 00 00 07 DE 30 14 25 10 34 25
					39 00 00 40 00 00 06 F0 55 AA 52 08 07
					15 00 00 40 00 00 02 B0 04
					//Vesa YUV 1.2 8_16 VESASPEC_1200x2670, slice 30
					15 00 00 40 00 00 02 90 03
					15 00 00 40 00 00 02 6F 01
					15 00 00 40 00 00 02 90 43
					39 00 00 40 00 00 13 91 AB F0 00 1E D1 00 01 D2 00 D4 00 32 03 97 11 48 11 50
					39 00 00 40 00 00 06 F0 55 AA 52 08 01
					15 00 00 40 00 00 02 6F 02
					/*lvd off*/
					39 00 00 40 00 00 03 C7 00 00
					/*GIR ON*/
					39 00 00 40 00 00 03 5F 00 00
					/*normal Gramma*/
					15 00 00 40 00 00 02 26 00
					/*Skip mode setting*/
					39 00 00 00 00 00 06 F0 55 AA 52 08 00
					15 00 00 40 00 00 02 6F 1C
					39 00 00 40 00 00 11 BA 01 01 01 01 01 01 01 03 01 01 01 03 00 00 00 00
					15 00 00 40 00 00 02 6F 2C
					39 00 00 40 00 00 11 BA 01 01 01 01 01 03 03 01 01 03 03 01 00 00 00 00
					15 00 00 40 00 00 02 6F 3C
					39 00 00 40 00 00 11 BA 01 01 01 01 01 04 04 03 01 04 04 03 00 00 00 00
					15 00 00 40 00 00 02 6F 4C
					39 00 00 40 00 00 11 BA 01 01 01 01 0B 0B 0B 0B 0B 0B 0B 0B 00 00 00 00
					15 00 00 40 00 00 02 6F 5C
					39 00 00 40 00 00 11 BA 01 01 01 01 01 01 01 01 01 01 01 01 01 01 01 01
					15 00 00 40 00 00 02 6F 6C
					39 00 00 40 00 00 09 BA 00 00 00 00 00 00 00 00
					15 00 00 40 00 00 02 6F 74
					39 00 00 40 00 00 11 BA 00 01 02 03 04 05 07 09 0B 77 EF 00 03 0B 0B 03
					15 00 00 40 00 00 02 6F 84
					39 00 00 40 00 00 11 BA 00 01 02 03 04 05 07 09 0B 77 EF 00 03 0B 0B 03
					15 00 00 40 00 00 02 6F 94
					39 00 00 40 00 00 11 BA 00 00 00 00 00 00 00 00 00 00 00 00 00 00 00 00
					15 00 00 40 00 00 02 6F A4
					39 00 00 40 00 00 11 BA 01 01 01 01 00 01 01 00 00 01 01 00 00 00 1E 00
					15 00 00 40 00 00 02 6F B4
					39 00 00 40 00 00 05 BA 00 55 19 0C
					15 00 00 40 00 00 02 6F B8
					39 00 00 40 00 00 09 BA 00 00 00 00 00 10 00 00
					15 00 00 40 00 00 02 6F C0
					39 00 00 40 00 00 09 BA 00 00 00 00 00 10 00 00
					15 00 00 40 00 00 02 6F 6E
					39 00 00 40 00 00 03 D1 03 C8
					15 00 00 40 00 00 02 2F 30
					/*30hz*/
					15 00 00 40 00 00 02 5A 00
					39 00 00 40 00 00 06 F0 55 AA 52 08 00
					15 00 00 40 00 00 02 6F DE
					15 00 00 40 00 00 02 BA 04
					15 00 00 40 00 00 02 6F 04
					15 00 00 40 00 00 02 35 03
					15 00 00 40 00 00 02 6F 14
					15 00 00 40 00 00 02 35 00
					15 00 00 40 00 00 02 8C 02
					15 00 00 00 00 00 02 6D 03
					/* ACL On */
					39 00 00 40 00 00 06 F0 55 AA 52 08 00
					15 00 00 40 00 00 02 6F 17
					39 00 00 40 00 00 0B B0 1A AF 1C 03 1D 57 1E AB 1F FF
					15 00 00 40 00 00 02 6F 25
					39 00 00 00 00 00 0D B0 01 FF 01 65 01 65 01 65 01 65 01 65
					15 00 00 40 00 00 02 6F 55
					39 00 00 00 00 00 07 B0 00 00 0D 18 23 2C
					/* Display On */
					05 00 00 00 78 00 01 11
					05 00 00 00 00 00 01 29
				];
				qcom,mdss-dsi-on-command-state = "dsi_lp_mode";

				qcom,mdss-dsi-timing-switch-command = [
					15 00 00 40 00 00 02 5A 00
					39 00 00 40 00 00 06 F0 55 AA 52 08 00
					15 00 00 40 00 00 02 6F DE
					15 00 00 40 00 00 02 BA 04
					15 00 00 40 00 00 02 6F 04
					15 00 00 40 00 00 02 35 03
					15 00 00 40 00 00 02 6F 14
					15 00 00 40 00 00 02 35 00
					15 00 00 40 00 00 02 8C 02
					15 00 00 00 00 00 02 6D 03
				];
				qcom,mdss-dsi-timing-switch-command-state = "dsi_lp_mode";

				qcom,mdss-dsi-nolp-command = [
					05 00 00 40 00 00 01 38
					39 00 00 00 00 00 03 51 00 00
				];
				qcom,mdss-dsi-nolp-command-update = <0x51 1 2>;
				qcom,mdss-dsi-nolp-command-state = "dsi_lp_mode";
			};

			timing@normal_24hz_index_05 {
				#include "dsi-panel-o3-36-02-0b-dsc-cmd-common.dtsi"
				cell-index = <5>;
				qcom,mdss-dsi-panel-framerate = <24>;
				qcom,mdss-dsi-h-sync-skew = <0>;
				qcom,disable-rsc-solver;
				qcom,mdss-dsi-on-command = [
					15 00 00 40 00 00 02 55 04
					39 00 00 40 00 00 03 81 01 19
					15 00 00 40 00 00 02 5A 01
					39 00 00 40 00 00 05 FF AA 55 A5 80
					15 00 00 40 00 00 02 6F 0A
					39 00 00 40 00 00 06 F6 70 70 70 70 70
					39 00 00 40 00 00 05 FF AA 55 A5 81
					15 00 00 40 00 00 02 6F 0D
					15 00 00 40 00 00 02 FB 80
					/*OSC Setting*/
					39 00 00 40 00 00 05 FF AA 55 A5 80
					15 00 00 40 00 00 02 6F 31
					39 00 00 40 00 00 03 F8 01 C4
					39 00 00 40 00 00 05 FF AA 55 A5 80
					15 00 00 40 00 00 02 6F 47
					15 00 00 40 00 00 02 F2 20
					15 00 00 40 00 00 02 6F 05
					15 00 00 40 00 00 02 F8 59
					15 00 00 40 00 00 02 6F 21
					15 00 00 40 00 00 02 F8 59
					39 00 00 40 00 00 05 FF AA 55 A5 81
					15 00 00 40 00 00 02 6F 0C
					15 00 00 40 00 00 02 FD 00
					15 00 00 40 00 00 02 6F 02
					15 00 00 40 00 00 02 F9 84
					15 00 00 40 00 00 02 6F 10
					15 00 00 40 00 00 02 FB 40
					39 00 00 40 00 00 05 FF AA 55 A5 80
					15 00 00 40 00 00 02 6F 48
					15 00 00 40 00 00 02 F2 00
					39 00 00 40 00 00 05 FF AA 55 A5 80
					15 00 00 40 00 00 02 6F 16
					39 00 00 40 00 00 03 F4 02 74
					39 00 00 40 00 00 05 FF AA 55 A5 80
					15 00 00 40 00 00 02 6F 42
					15 00 00 40 00 00 02 F4 00
					39 00 00 40 00 00 05 FF AA 55 A5 80
					15 00 00 40 00 00 02 6F 49
					15 00 00 40 00 00 02 F2 10
					39 00 00 40 00 00 05 FF AA 55 A5 81
					15 00 00 40 00 00 02 6F 05
					39 00 00 40 00 00 03 FE 3C 3C
					39 00 00 40 00 00 05 FF AA 55 A5 82
					15 00 00 40 00 00 02 6F 09
					15 00 00 40 00 00 02 F2 FF
					39 00 00 40 00 00 05 FF AA 55 A5 80
					15 00 00 40 00 00 02 6F 04
					15 00 00 40 00 00 02 F2 3C
					15 00 00 40 00 00 02 17 30
					/*120hz*/
					15 00 00 40 00 00 02 2F 00
					/*TE ON*/
					15 00 00 40 00 00 02 35 00
					/*600nit*/
					39 00 00 40 00 00 03 51 00 00
					15 00 00 40 00 00 02 6F 04
					/*AOD 60nit*/
					39 00 00 40 00 00 03 51 07 FF
					15 00 00 40 00 00 02 53 20
					39 00 00 40 00 00 05 2A 00 00 04 AF
					39 00 00 40 00 00 05 2B 00 00 0A 6D
					39 00 00 40 00 00 06 F0 55 AA 52 08 03
					15 00 00 00 00 00 02 6F 09
					39 00 00 40 00 00 07 DE 30 14 25 10 34 25
					39 00 00 40 00 00 06 F0 55 AA 52 08 07
					15 00 00 40 00 00 02 B0 04
					//Vesa YUV 1.2 8_16 VESASPEC_1200x2670, slice 30
					15 00 00 40 00 00 02 90 03
					15 00 00 40 00 00 02 6F 01
					15 00 00 40 00 00 02 90 43
					39 00 00 40 00 00 13 91 AB F0 00 1E D1 00 01 D2 00 D4 00 32 03 97 11 48 11 50
					39 00 00 40 00 00 06 F0 55 AA 52 08 01
					15 00 00 40 00 00 02 6F 02
					/*lvd off*/
					39 00 00 40 00 00 03 C7 00 00
					/*GIR ON*/
					39 00 00 40 00 00 03 5F 00 00
					/*normal Gramma*/
					15 00 00 40 00 00 02 26 00
					/*Skip mode setting*/
					39 00 00 00 00 00 06 F0 55 AA 52 08 00
					15 00 00 40 00 00 02 6F 1C
					39 00 00 40 00 00 11 BA 01 01 01 01 01 01 01 03 01 01 01 03 00 00 00 00
					15 00 00 40 00 00 02 6F 2C
					39 00 00 40 00 00 11 BA 01 01 01 01 01 03 03 01 01 03 03 01 00 00 00 00
					15 00 00 40 00 00 02 6F 3C
					39 00 00 40 00 00 11 BA 01 01 01 01 01 04 04 03 01 04 04 03 00 00 00 00
					15 00 00 40 00 00 02 6F 4C
					39 00 00 40 00 00 11 BA 01 01 01 01 0B 0B 0B 0B 0B 0B 0B 0B 00 00 00 00
					15 00 00 40 00 00 02 6F 5C
					39 00 00 40 00 00 11 BA 01 01 01 01 01 01 01 01 01 01 01 01 01 01 01 01
					15 00 00 40 00 00 02 6F 6C
					39 00 00 40 00 00 09 BA 00 00 00 00 00 00 00 00
					15 00 00 40 00 00 02 6F 74
					39 00 00 40 00 00 11 BA 00 01 02 03 04 05 07 09 0B 77 EF 00 03 0B 0B 03
					15 00 00 40 00 00 02 6F 84
					39 00 00 40 00 00 11 BA 00 01 02 03 04 05 07 09 0B 77 EF 00 03 0B 0B 03
					15 00 00 40 00 00 02 6F 94
					39 00 00 40 00 00 11 BA 00 00 00 00 00 00 00 00 00 00 00 00 00 00 00 00
					15 00 00 40 00 00 02 6F A4
					39 00 00 40 00 00 11 BA 01 01 01 01 00 01 01 00 00 01 01 00 00 00 1E 00
					15 00 00 40 00 00 02 6F B4
					39 00 00 40 00 00 05 BA 00 55 19 0C
					15 00 00 40 00 00 02 6F B8
					39 00 00 40 00 00 09 BA 00 00 00 00 00 10 00 00
					15 00 00 40 00 00 02 6F C0
					39 00 00 40 00 00 09 BA 00 00 00 00 00 10 00 00
					15 00 00 40 00 00 02 6F 6E
					39 00 00 40 00 00 03 D1 03 C8
					15 00 00 40 00 00 02 2F 30
					/*24hz*/
					15 00 00 40 00 00 02 5A 00
					39 00 00 40 00 00 06 F0 55 AA 52 08 00
					15 00 00 40 00 00 02 6F DE
					15 00 00 40 00 00 02 BA 04
					15 00 00 40 00 00 02 6F 04
					15 00 00 40 00 00 02 35 04
					15 00 00 40 00 00 02 6F 14
					15 00 00 40 00 00 02 35 00
					15 00 00 40 00 00 02 8C 02
					15 00 00 00 00 00 02 6D 04
					/* ACL On */
					39 00 00 40 00 00 06 F0 55 AA 52 08 00
					15 00 00 40 00 00 02 6F 17
					39 00 00 40 00 00 0B B0 1A AF 1C 03 1D 57 1E AB 1F FF
					15 00 00 40 00 00 02 6F 25
					39 00 00 00 00 00 0D B0 01 FF 01 65 01 65 01 65 01 65 01 65
					15 00 00 40 00 00 02 6F 55
					39 00 00 00 00 00 07 B0 00 00 0D 18 23 2C
					/* Display On */
					05 00 00 00 78 00 01 11
					05 00 00 00 00 00 01 29
				];
				qcom,mdss-dsi-on-command-state = "dsi_lp_mode";

				qcom,mdss-dsi-timing-switch-command = [
					15 00 00 40 00 00 02 5A 00
					39 00 00 40 00 00 06 F0 55 AA 52 08 00
					15 00 00 40 00 00 02 6F DE
					15 00 00 40 00 00 02 BA 04
					15 00 00 40 00 00 02 6F 04
					15 00 00 40 00 00 02 35 04
					15 00 00 40 00 00 02 6F 14
					15 00 00 40 00 00 02 35 00
					15 00 00 40 00 00 02 8C 02
					15 00 00 00 00 00 02 6D 04
				];
				qcom,mdss-dsi-timing-switch-command-state = "dsi_lp_mode";

				qcom,mdss-dsi-nolp-command = [
					05 00 00 40 00 00 01 38
					39 00 00 00 00 00 03 51 00 00
				];
				qcom,mdss-dsi-nolp-command-update = <0x51 1 2>;
				qcom,mdss-dsi-nolp-command-state = "dsi_lp_mode";
			};

			timing@auto_120_to_1hz_index_06 {
				#include "dsi-panel-o3-36-02-0b-dsc-cmd-common.dtsi"
				cell-index = <6>;
				qcom,mdss-dsi-panel-framerate = <120>;
				/* ---------------------------- */
				/* | 15 - 14 | 13 - 7 | 6 - 0 | */
				/* ---------------------------- */
				/* |   mode  | sf fps | min fps| */
				/* ---------------------------- -*/
				/* mode: 1 idle, 2 auto, 3 qsync */
				/*   2 << 14 | 120 << 7 | 1     */
				qcom,mdss-dsi-h-sync-skew = <48129>;
				mi,mdss-dsi-ddic-mode = "auto";
				mi,mdss-dsi-sf-framerate = <120>;
				mi,mdss-dsi-ddic-min-framerate = <1>;

				qcom,mdss-dsi-on-command = [
					15 00 00 40 00 00 02 55 04
					39 00 00 40 00 00 03 81 01 19
					15 00 00 40 00 00 02 5A 01
					39 00 00 40 00 00 05 FF AA 55 A5 80
					15 00 00 40 00 00 02 6F 0A
					39 00 00 40 00 00 06 F6 70 70 70 70 70
					39 00 00 40 00 00 05 FF AA 55 A5 81
					15 00 00 40 00 00 02 6F 0D
					15 00 00 40 00 00 02 FB 80
					/*OSC Setting*/
					39 00 00 40 00 00 05 FF AA 55 A5 80
					15 00 00 40 00 00 02 6F 31
					39 00 00 40 00 00 03 F8 01 C4
					39 00 00 40 00 00 05 FF AA 55 A5 80
					15 00 00 40 00 00 02 6F 47
					15 00 00 40 00 00 02 F2 20
					15 00 00 40 00 00 02 6F 05
					15 00 00 40 00 00 02 F8 59
					15 00 00 40 00 00 02 6F 21
					15 00 00 40 00 00 02 F8 59
					39 00 00 40 00 00 05 FF AA 55 A5 81
					15 00 00 40 00 00 02 6F 0C
					15 00 00 40 00 00 02 FD 00
					15 00 00 40 00 00 02 6F 02
					15 00 00 40 00 00 02 F9 84
					15 00 00 40 00 00 02 6F 10
					15 00 00 40 00 00 02 FB 40
					39 00 00 40 00 00 05 FF AA 55 A5 80
					15 00 00 40 00 00 02 6F 48
					15 00 00 40 00 00 02 F2 00
					39 00 00 40 00 00 05 FF AA 55 A5 80
					15 00 00 40 00 00 02 6F 16
					39 00 00 40 00 00 03 F4 02 74
					39 00 00 40 00 00 05 FF AA 55 A5 80
					15 00 00 40 00 00 02 6F 42
					15 00 00 40 00 00 02 F4 00
					39 00 00 40 00 00 05 FF AA 55 A5 80
					15 00 00 40 00 00 02 6F 49
					15 00 00 40 00 00 02 F2 10
					39 00 00 40 00 00 05 FF AA 55 A5 81
					15 00 00 40 00 00 02 6F 05
					39 00 00 40 00 00 03 FE 3C 3C
					39 00 00 40 00 00 05 FF AA 55 A5 82
					15 00 00 40 00 00 02 6F 09
					15 00 00 40 00 00 02 F2 FF
					39 00 00 40 00 00 05 FF AA 55 A5 80
					15 00 00 40 00 00 02 6F 04
					15 00 00 40 00 00 02 F2 3C
					15 00 00 40 00 00 02 17 30
					/*120hz*/
					15 00 00 40 00 00 02 2F 00
					/*TE ON*/
					15 00 00 40 00 00 02 35 00
					/*600nit*/
					39 00 00 40 00 00 03 51 00 00
					15 00 00 40 00 00 02 6F 04
					/*AOD 60nit*/
					39 00 00 40 00 00 03 51 07 FF
					15 00 00 40 00 00 02 53 20
					39 00 00 40 00 00 05 2A 00 00 04 AF
					39 00 00 40 00 00 05 2B 00 00 0A 6D
					39 00 00 40 00 00 06 F0 55 AA 52 08 03
					15 00 00 00 00 00 02 6F 09
					39 00 00 40 00 00 07 DE 30 14 25 10 34 25
					39 00 00 40 00 00 06 F0 55 AA 52 08 07
					15 00 00 40 00 00 02 B0 04
					//Vesa YUV 1.2 8_16 VESASPEC_1200x2670, slice 30
					15 00 00 40 00 00 02 90 03
					15 00 00 40 00 00 02 6F 01
					15 00 00 40 00 00 02 90 43
					39 00 00 40 00 00 13 91 AB F0 00 1E D1 00 01 D2 00 D4 00 32 03 97 11 48 11 50
					39 00 00 40 00 00 06 F0 55 AA 52 08 01
					15 00 00 40 00 00 02 6F 02
					/*lvd off*/
					39 00 00 40 00 00 03 C7 00 00
					/*GIR ON*/
					39 00 00 40 00 00 03 5F 00 00
					/*normal Gramma*/
					15 00 00 40 00 00 02 26 00
					/*Skip mode setting*/
					39 00 00 00 00 00 06 F0 55 AA 52 08 00
					15 00 00 40 00 00 02 6F 1C
					39 00 00 40 00 00 11 BA 01 01 01 01 01 01 01 03 01 01 01 03 00 00 00 00
					15 00 00 40 00 00 02 6F 2C
					39 00 00 40 00 00 11 BA 01 01 01 01 01 03 03 01 01 03 03 01 00 00 00 00
					15 00 00 40 00 00 02 6F 3C
					39 00 00 40 00 00 11 BA 01 01 01 01 01 04 04 03 01 04 04 03 00 00 00 00
					15 00 00 40 00 00 02 6F 4C
					39 00 00 40 00 00 11 BA 01 01 01 01 0B 0B 0B 0B 0B 0B 0B 0B 00 00 00 00
					15 00 00 40 00 00 02 6F 5C
					39 00 00 40 00 00 11 BA 01 01 01 01 01 01 01 01 01 01 01 01 01 01 01 01
					15 00 00 40 00 00 02 6F 6C
					39 00 00 40 00 00 09 BA 00 00 00 00 00 00 00 00
					15 00 00 40 00 00 02 6F 74
					39 00 00 40 00 00 11 BA 00 01 02 03 04 05 07 09 0B 77 EF 00 03 0B 0B 03
					15 00 00 40 00 00 02 6F 84
					39 00 00 40 00 00 11 BA 00 01 02 03 04 05 07 09 0B 77 EF 00 03 0B 0B 03
					15 00 00 40 00 00 02 6F 94
					39 00 00 40 00 00 11 BA 00 00 00 00 00 00 00 00 00 00 00 00 00 00 00 00
					15 00 00 40 00 00 02 6F A4
					39 00 00 40 00 00 11 BA 01 01 01 01 00 01 01 00 00 01 01 00 00 00 1E 00
					15 00 00 40 00 00 02 6F B4
					39 00 00 40 00 00 05 BA 00 55 19 0C
					15 00 00 40 00 00 02 6F B8
					39 00 00 40 00 00 09 BA 00 00 00 00 00 10 00 00
					15 00 00 40 00 00 02 6F C0
					39 00 00 40 00 00 09 BA 00 00 00 00 00 10 00 00
					15 00 00 40 00 00 02 6F 6E
					39 00 00 40 00 00 03 D1 03 C8
					15 00 00 40 00 00 02 2F 30
					/*auto 120hz*/
					15 00 00 40 00 00 02 5A 00
					39 00 00 40 00 00 06 F0 55 AA 52 08 00
					15 00 00 40 00 00 02 6F D9
					15 00 00 40 00 00 02 BA 00
					15 00 00 40 00 00 02 6F 04
					15 00 00 40 00 00 02 35 00
					15 00 00 40 00 00 02 6F 14
					15 00 00 40 00 00 02 35 00
					39 00 00 40 00 00 04 8C 00 00 11
					15 00 00 00 00 00 02 6D 09
					/* ACL On */
					39 00 00 40 00 00 06 F0 55 AA 52 08 00
					15 00 00 40 00 00 02 6F 17
					39 00 00 40 00 00 0B B0 1A AF 1C 03 1D 57 1E AB 1F FF
					15 00 00 40 00 00 02 6F 25
					39 00 00 00 00 00 0D B0 01 FF 01 65 01 65 01 65 01 65 01 65
					15 00 00 40 00 00 02 6F 55
					39 00 00 00 00 00 07 B0 00 00 0D 18 23 2C
					/* Display On */
					05 00 00 00 78 00 01 11
					05 00 00 00 00 00 01 29
				];
				qcom,mdss-dsi-on-command-state = "dsi_lp_mode";

				qcom,mdss-dsi-timing-switch-command = [
					15 00 00 40 00 00 02 5A 00
					39 00 00 40 00 00 06 F0 55 AA 52 08 00
					15 00 00 40 00 00 02 6F D9
					15 00 00 40 00 00 02 BA 00
					15 00 00 40 00 00 02 6F 04
					15 00 00 40 00 00 02 35 00
					15 00 00 40 00 00 02 6F 14
					15 00 00 40 00 00 02 35 00
					39 00 00 40 00 00 04 8C 00 00 11
					15 00 00 00 00 00 02 6D 09
				];
				qcom,mdss-dsi-timing-switch-command-state = "dsi_lp_mode";

				qcom,mdss-dsi-nolp-command = [
					05 00 00 40 00 00 01 38
					39 00 00 00 00 00 03 51 00 00
				];
				qcom,mdss-dsi-nolp-command-update = <0x51 1 2>;
				qcom,mdss-dsi-nolp-command-state = "dsi_lp_mode";
			};

			timing@idle_120_to_1hz_index_07 {
				#include "dsi-panel-o3-36-02-0b-dsc-cmd-common.dtsi"
				cell-index = <7>;
				qcom,mdss-dsi-panel-framerate = <120>;
				/* ---------------------------- */
				/* | 15 - 14 | 13 - 7 | 6 - 0 | */
				/* ---------------------------- */
				/* |   mode  | sf fps | min fps| */
				/* ---------------------------- -*/
				/* mode: 1 idle, 2 auto, 3 qsync */
				/*   1 << 14 | 120 << 7 | 1     */
				qcom,mdss-dsi-h-sync-skew = <31745>;
				mi,mdss-dsi-ddic-mode = "idle";
				mi,mdss-dsi-sf-framerate = <120>;
				mi,mdss-dsi-ddic-min-framerate = <1>;

				qcom,mdss-dsi-on-command = [
					15 00 00 40 00 00 02 55 04
					39 00 00 40 00 00 03 81 01 19
					15 00 00 40 00 00 02 5A 01
					39 00 00 40 00 00 05 FF AA 55 A5 80
					15 00 00 40 00 00 02 6F 0A
					39 00 00 40 00 00 06 F6 70 70 70 70 70
					39 00 00 40 00 00 05 FF AA 55 A5 81
					15 00 00 40 00 00 02 6F 0D
					15 00 00 40 00 00 02 FB 80
					/*OSC Setting*/
					39 00 00 40 00 00 05 FF AA 55 A5 80
					15 00 00 40 00 00 02 6F 31
					39 00 00 40 00 00 03 F8 01 C4
					39 00 00 40 00 00 05 FF AA 55 A5 80
					15 00 00 40 00 00 02 6F 47
					15 00 00 40 00 00 02 F2 20
					15 00 00 40 00 00 02 6F 05
					15 00 00 40 00 00 02 F8 59
					15 00 00 40 00 00 02 6F 21
					15 00 00 40 00 00 02 F8 59
					39 00 00 40 00 00 05 FF AA 55 A5 81
					15 00 00 40 00 00 02 6F 0C
					15 00 00 40 00 00 02 FD 00
					15 00 00 40 00 00 02 6F 02
					15 00 00 40 00 00 02 F9 84
					15 00 00 40 00 00 02 6F 10
					15 00 00 40 00 00 02 FB 40
					39 00 00 40 00 00 05 FF AA 55 A5 80
					15 00 00 40 00 00 02 6F 48
					15 00 00 40 00 00 02 F2 00
					39 00 00 40 00 00 05 FF AA 55 A5 80
					15 00 00 40 00 00 02 6F 16
					39 00 00 40 00 00 03 F4 02 74
					39 00 00 40 00 00 05 FF AA 55 A5 80
					15 00 00 40 00 00 02 6F 42
					15 00 00 40 00 00 02 F4 00
					39 00 00 40 00 00 05 FF AA 55 A5 80
					15 00 00 40 00 00 02 6F 49
					15 00 00 40 00 00 02 F2 10
					39 00 00 40 00 00 05 FF AA 55 A5 81
					15 00 00 40 00 00 02 6F 05
					39 00 00 40 00 00 03 FE 3C 3C
					39 00 00 40 00 00 05 FF AA 55 A5 82
					15 00 00 40 00 00 02 6F 09
					15 00 00 40 00 00 02 F2 FF
					39 00 00 40 00 00 05 FF AA 55 A5 80
					15 00 00 40 00 00 02 6F 04
					15 00 00 40 00 00 02 F2 3C
					15 00 00 40 00 00 02 17 30
					/*120hz*/
					15 00 00 40 00 00 02 2F 00
					/*TE ON*/
					15 00 00 40 00 00 02 35 00
					/*600nit*/
					39 00 00 40 00 00 03 51 00 00
					15 00 00 40 00 00 02 6F 04
					/*AOD 60nit*/
					39 00 00 40 00 00 03 51 07 FF
					15 00 00 40 00 00 02 53 20
					39 00 00 40 00 00 05 2A 00 00 04 AF
					39 00 00 40 00 00 05 2B 00 00 0A 6D
					39 00 00 40 00 00 06 F0 55 AA 52 08 03
					15 00 00 00 00 00 02 6F 09
					39 00 00 40 00 00 07 DE 30 14 25 10 34 25
					39 00 00 40 00 00 06 F0 55 AA 52 08 07
					15 00 00 40 00 00 02 B0 04
					//Vesa YUV 1.2 8_16 VESASPEC_1200x2670, slice 30
					15 00 00 40 00 00 02 90 03
					15 00 00 40 00 00 02 6F 01
					15 00 00 40 00 00 02 90 43
					39 00 00 40 00 00 13 91 AB F0 00 1E D1 00 01 D2 00 D4 00 32 03 97 11 48 11 50
					39 00 00 40 00 00 06 F0 55 AA 52 08 01
					15 00 00 40 00 00 02 6F 02
					/*lvd off*/
					39 00 00 40 00 00 03 C7 00 00
					/*GIR ON*/
					39 00 00 40 00 00 03 5F 00 00
					/*normal Gramma*/
					15 00 00 40 00 00 02 26 00
					/*Skip mode setting*/
					39 00 00 00 00 00 06 F0 55 AA 52 08 00
					15 00 00 40 00 00 02 6F 1C
					39 00 00 40 00 00 11 BA 01 01 01 01 01 01 01 03 01 01 01 03 00 00 00 00
					15 00 00 40 00 00 02 6F 2C
					39 00 00 40 00 00 11 BA 01 01 01 01 01 03 03 01 01 03 03 01 00 00 00 00
					15 00 00 40 00 00 02 6F 3C
					39 00 00 40 00 00 11 BA 01 01 01 01 01 04 04 03 01 04 04 03 00 00 00 00
					15 00 00 40 00 00 02 6F 4C
					39 00 00 40 00 00 11 BA 01 01 01 01 0B 0B 0B 0B 0B 0B 0B 0B 00 00 00 00
					15 00 00 40 00 00 02 6F 5C
					39 00 00 40 00 00 11 BA 01 01 01 01 01 01 01 01 01 01 01 01 01 01 01 01
					15 00 00 40 00 00 02 6F 6C
					39 00 00 40 00 00 09 BA 00 00 00 00 00 00 00 00
					15 00 00 40 00 00 02 6F 74
					39 00 00 40 00 00 11 BA 00 01 02 03 04 05 07 09 0B 77 EF 00 03 0B 0B 03
					15 00 00 40 00 00 02 6F 84
					39 00 00 40 00 00 11 BA 00 01 02 03 04 05 07 09 0B 77 EF 00 03 0B 0B 03
					15 00 00 40 00 00 02 6F 94
					39 00 00 40 00 00 11 BA 00 00 00 00 00 00 00 00 00 00 00 00 00 00 00 00
					15 00 00 40 00 00 02 6F A4
					39 00 00 40 00 00 11 BA 01 01 01 01 00 01 01 00 00 01 01 00 00 00 1E 00
					15 00 00 40 00 00 02 6F B4
					39 00 00 40 00 00 05 BA 00 55 19 0C
					15 00 00 40 00 00 02 6F B8
					39 00 00 40 00 00 09 BA 00 00 00 00 00 10 00 00
					15 00 00 40 00 00 02 6F C0
					39 00 00 40 00 00 09 BA 00 00 00 00 00 10 00 00
					15 00 00 40 00 00 02 6F 6E
					39 00 00 40 00 00 03 D1 03 C8
					15 00 00 40 00 00 02 2F 30
					/*idle 120hz*/
					15 00 00 40 00 00 02 5A 00
					39 00 00 40 00 00 06 F0 55 AA 52 08 00
					15 00 00 40 00 00 02 6F D9
					15 00 00 40 00 00 02 BA 00
					15 00 00 40 00 00 02 6F 04
					15 00 00 40 00 00 02 35 00
					15 00 00 40 00 00 02 6F 14
					15 00 00 40 00 00 02 35 00
					39 00 00 40 00 00 04 8C 00 00 11
					15 00 00 00 00 00 02 6D 09
					/* ACL On */
					39 00 00 40 00 00 06 F0 55 AA 52 08 00
					15 00 00 40 00 00 02 6F 17
					39 00 00 40 00 00 0B B0 1A AF 1C 03 1D 57 1E AB 1F FF
					15 00 00 40 00 00 02 6F 25
					39 00 00 00 00 00 0D B0 01 FF 01 65 01 65 01 65 01 65 01 65
					15 00 00 40 00 00 02 6F 55
					39 00 00 00 00 00 07 B0 00 00 0D 18 23 2C
					/* Display On */
					05 00 00 00 78 00 01 11
					05 00 00 00 00 00 01 29
				];
				qcom,mdss-dsi-on-command-state = "dsi_lp_mode";

				qcom,mdss-dsi-timing-switch-command = [
					15 00 00 40 00 00 02 5A 00
					39 00 00 40 00 00 06 F0 55 AA 52 08 00
					15 00 00 40 00 00 02 6F D9
					15 00 00 40 00 00 02 BA 00
					15 00 00 40 00 00 02 6F 04
					15 00 00 40 00 00 02 35 00
					15 00 00 40 00 00 02 6F 14
					15 00 00 40 00 00 02 35 00
					39 00 00 40 00 00 04 8C 00 00 11
					15 00 00 00 00 00 02 6D 09
				];
				qcom,mdss-dsi-timing-switch-command-state = "dsi_lp_mode";

				qcom,mdss-dsi-nolp-command = [
					05 00 00 40 00 00 01 38
					39 00 00 00 00 00 03 51 00 00
				];
				qcom,mdss-dsi-nolp-command-update = <0x51 1 2>;
				qcom,mdss-dsi-nolp-command-state = "dsi_lp_mode";
			};

			timing@wqhd_test_120_to_0.5hz_index_08 {
				#include "dsi-panel-o3-36-02-0b-dsc-cmd-common.dtsi"
				cell-index = <8>;
				qcom,mdss-dsi-panel-framerate = <120>;
				/* ---------------------------- */
				/* | 15 - 14 | 13 - 7 | 6 - 0 | */
				/* ---------------------------- */
				/* |   mode  | sf fps | min fps| */
				/* ---------------------------- -*/
				/* mode: 1 idle, 2 auto, 3 qsync */
				/*   1 << 14 | 120 << 7 | 127    */
				qcom,mdss-dsi-h-sync-skew = <31871>;
				/* mode: 0 normal, 1 idle, 2 auto, 3 qsync, 4 diff, 5 test */
				mi,mdss-dsi-ddic-mode = "test";
				mi,mdss-dsi-sf-framerate = <120>;
				mi,mdss-dsi-ddic-min-framerate = <127>;

				qcom,mdss-dsi-on-command = [
					15 00 00 40 00 00 02 55 04
					39 00 00 40 00 00 03 81 01 19
					15 00 00 40 00 00 02 5A 01
					39 00 00 40 00 00 05 FF AA 55 A5 80
					15 00 00 40 00 00 02 6F 0A
					39 00 00 40 00 00 06 F6 70 70 70 70 70
					39 00 00 40 00 00 05 FF AA 55 A5 81
					15 00 00 40 00 00 02 6F 0D
					15 00 00 40 00 00 02 FB 80
					/*OSC Setting*/
					39 00 00 40 00 00 05 FF AA 55 A5 80
					15 00 00 40 00 00 02 6F 31
					39 00 00 40 00 00 03 F8 01 C4
					39 00 00 40 00 00 05 FF AA 55 A5 80
					15 00 00 40 00 00 02 6F 47
					15 00 00 40 00 00 02 F2 20
					15 00 00 40 00 00 02 6F 05
					15 00 00 40 00 00 02 F8 59
					15 00 00 40 00 00 02 6F 21
					15 00 00 40 00 00 02 F8 59
					39 00 00 40 00 00 05 FF AA 55 A5 81
					15 00 00 40 00 00 02 6F 0C
					15 00 00 40 00 00 02 FD 00
					15 00 00 40 00 00 02 6F 02
					15 00 00 40 00 00 02 F9 84
					15 00 00 40 00 00 02 6F 10
					15 00 00 40 00 00 02 FB 40
					39 00 00 40 00 00 05 FF AA 55 A5 80
					15 00 00 40 00 00 02 6F 48
					15 00 00 40 00 00 02 F2 00
					39 00 00 40 00 00 05 FF AA 55 A5 80
					15 00 00 40 00 00 02 6F 16
					39 00 00 40 00 00 03 F4 02 74
					39 00 00 40 00 00 05 FF AA 55 A5 80
					15 00 00 40 00 00 02 6F 42
					15 00 00 40 00 00 02 F4 00
					39 00 00 40 00 00 05 FF AA 55 A5 80
					15 00 00 40 00 00 02 6F 49
					15 00 00 40 00 00 02 F2 10
					39 00 00 40 00 00 05 FF AA 55 A5 81
					15 00 00 40 00 00 02 6F 05
					39 00 00 40 00 00 03 FE 3C 3C
					39 00 00 40 00 00 05 FF AA 55 A5 82
					15 00 00 40 00 00 02 6F 09
					15 00 00 40 00 00 02 F2 FF
					39 00 00 40 00 00 05 FF AA 55 A5 80
					15 00 00 40 00 00 02 6F 04
					15 00 00 40 00 00 02 F2 3C
					15 00 00 40 00 00 02 17 30
					/*120hz*/
					15 00 00 40 00 00 02 2F 00
					/*TE ON*/
					15 00 00 40 00 00 02 35 00
					/*600nit*/
					39 00 00 40 00 00 03 51 00 00
					15 00 00 40 00 00 02 6F 04
					/*AOD 60nit*/
					39 00 00 40 00 00 03 51 07 FF
					15 00 00 40 00 00 02 53 20
					39 00 00 40 00 00 05 2A 00 00 04 AF
					39 00 00 40 00 00 05 2B 00 00 0A 6D
					39 00 00 40 00 00 06 F0 55 AA 52 08 03
					15 00 00 00 00 00 02 6F 09
					39 00 00 40 00 00 07 DE 30 14 25 10 34 25
					39 00 00 40 00 00 06 F0 55 AA 52 08 07
					15 00 00 40 00 00 02 B0 04
					//Vesa YUV 1.2 8_16 VESASPEC_1200x2670, slice 30
					15 00 00 40 00 00 02 90 03
					15 00 00 40 00 00 02 6F 01
					15 00 00 40 00 00 02 90 43
					39 00 00 40 00 00 13 91 AB F0 00 1E D1 00 01 D2 00 D4 00 32 03 97 11 48 11 50
					39 00 00 40 00 00 06 F0 55 AA 52 08 01
					15 00 00 40 00 00 02 6F 02
					/*lvd off*/
					39 00 00 40 00 00 03 C7 00 00
					/*GIR ON*/
					39 00 00 40 00 00 03 5F 00 00
					/*normal Gramma*/
					15 00 00 40 00 00 02 26 00
					/*Skip mode setting*/
					39 00 00 00 00 00 06 F0 55 AA 52 08 00
					15 00 00 40 00 00 02 6F 1C
					39 00 00 40 00 00 11 BA 01 01 01 01 01 01 01 03 01 01 01 03 00 00 00 00
					15 00 00 40 00 00 02 6F 2C
					39 00 00 40 00 00 11 BA 01 01 01 01 01 03 03 01 01 03 03 01 00 00 00 00
					15 00 00 40 00 00 02 6F 3C
					39 00 00 40 00 00 11 BA 01 01 01 01 01 04 04 03 01 04 04 03 00 00 00 00
					15 00 00 40 00 00 02 6F 4C
					39 00 00 40 00 00 11 BA 01 01 01 01 0B 0B 0B 0B 0B 0B 0B 0B 00 00 00 00
					15 00 00 40 00 00 02 6F 5C
					39 00 00 40 00 00 11 BA 01 01 01 01 01 01 01 01 01 01 01 01 01 01 01 01
					15 00 00 40 00 00 02 6F 6C
					39 00 00 40 00 00 09 BA 00 00 00 00 00 00 00 00
					15 00 00 40 00 00 02 6F 74
					39 00 00 40 00 00 11 BA 00 01 02 03 04 05 07 09 0B 77 EF 00 03 0B 0B 03
					15 00 00 40 00 00 02 6F 84
					39 00 00 40 00 00 11 BA 00 01 02 03 04 05 07 09 0B 77 EF 00 03 0B 0B 03
					15 00 00 40 00 00 02 6F 94
					39 00 00 40 00 00 11 BA 00 00 00 00 00 00 00 00 00 00 00 00 00 00 00 00
					15 00 00 40 00 00 02 6F A4
					39 00 00 40 00 00 11 BA 01 01 01 01 00 01 01 00 00 01 01 00 00 00 1E 00
					15 00 00 40 00 00 02 6F B4
					39 00 00 40 00 00 05 BA 00 55 19 0C
					15 00 00 40 00 00 02 6F B8
					39 00 00 40 00 00 09 BA 00 00 00 00 00 10 00 00
					15 00 00 40 00 00 02 6F C0
					39 00 00 40 00 00 09 BA 00 00 00 00 00 10 00 00
					15 00 00 40 00 00 02 6F 6E
					39 00 00 40 00 00 03 D1 03 C8
					15 00 00 40 00 00 02 2F 30
					/*0.5hz*/
					15 00 00 40 00 00 02 5A 00
					39 00 00 40 00 00 06 F0 55 AA 52 08 00
					15 00 00 40 00 00 02 6F DE
					15 00 00 40 00 00 02 BA 00
					15 00 00 40 00 00 02 6F 04
					15 00 00 40 00 00 02 35 01
					15 00 00 40 00 00 02 6F 14
					15 00 00 40 00 00 02 35 00
					15 00 00 40 00 00 02 8C 00
					15 00 00 00 00 00 02 6D 0A
					/* ACL On */
					39 00 00 40 00 00 06 F0 55 AA 52 08 00
					15 00 00 40 00 00 02 6F 17
					39 00 00 40 00 00 0B B0 1A AF 1C 03 1D 57 1E AB 1F FF
					15 00 00 40 00 00 02 6F 25
					39 00 00 00 00 00 0D B0 01 FF 01 65 01 65 01 65 01 65 01 65
					15 00 00 40 00 00 02 6F 55
					39 00 00 00 00 00 07 B0 00 00 0D 18 23 2C
					/* Display On */
					05 00 00 00 78 00 01 11
					05 00 00 00 00 00 01 29
				];
				qcom,mdss-dsi-on-command-state = "dsi_lp_mode";

				qcom,mdss-dsi-timing-switch-command = [
					15 00 00 40 00 00 02 5A 00
					39 00 00 40 00 00 06 F0 55 AA 52 08 00
					15 00 00 40 00 00 02 6F DE
					15 00 00 40 00 00 02 BA 00
					15 00 00 40 00 00 02 6F 04
					15 00 00 40 00 00 02 35 01
					15 00 00 40 00 00 02 6F 14
					15 00 00 40 00 00 02 35 00
					15 00 00 40 00 00 02 8C 00
					15 00 00 00 00 00 02 6D 0A
				];
				qcom,mdss-dsi-timing-switch-command-state = "dsi_lp_mode";

				qcom,mdss-dsi-nolp-command = [
					05 00 00 40 00 00 01 38
					39 00 00 00 00 00 03 51 00 00
				];
				qcom,mdss-dsi-nolp-command-update = <0x51 1 2>;
				qcom,mdss-dsi-nolp-command-state = "dsi_lp_mode";
			};
		};
	};
};

&dsi_o3_36_02_0b_dsc_cmd {
	qcom,panel-supply-entries = <&dsi_panel_pwr_supply_O3>;
	qcom,panel-global-supply-entries = <&dsi_panel_pwr_supply_O3GL>;
	qcom,mdss-dsi-bl-pmic-control-type = "bl_ctrl_dcs";
	qcom,mdss-dsi-bl-min-level = <25>;
	qcom,mdss-dsi-bl-max-level = <8191>;
	qcom,bl-dsc-cmd-state = "dsi_hs_mode";
	qcom,mdss-brightness-max-level = <8191>;
	qcom,mdss-brightness-init-level = <307>;
	qcom,platform-reset-gpio = <&tlmm 98 0>;

	mi,panel-supply-different-by-country;
	mi,panel-build-id-read-needed;
	mi,panel-build-id-read-length = <1>;
	mi,mdss-dsi-panel-build-id-read-command = [06 01 00 01 00 00 01 DA];
	mi,mdss-dsi-panel-build-id-read-command-state = "dsi_hs_mode";

	//mi,disable-ic-dimming-flag;
	qcom,mdss-dsi-panel-vsync-delay;
	qcom,ulps-enabled;
	qcom,dsi-select-clocks = "pll_byte_clk0", "pll_dsi_clk0";
	qcom,mdss-dsi-clk-strength = <0xFF>;
};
